AUTOSAR XML (schema 4-2-2)
package /STELLANTIS/EPT/ASWCs
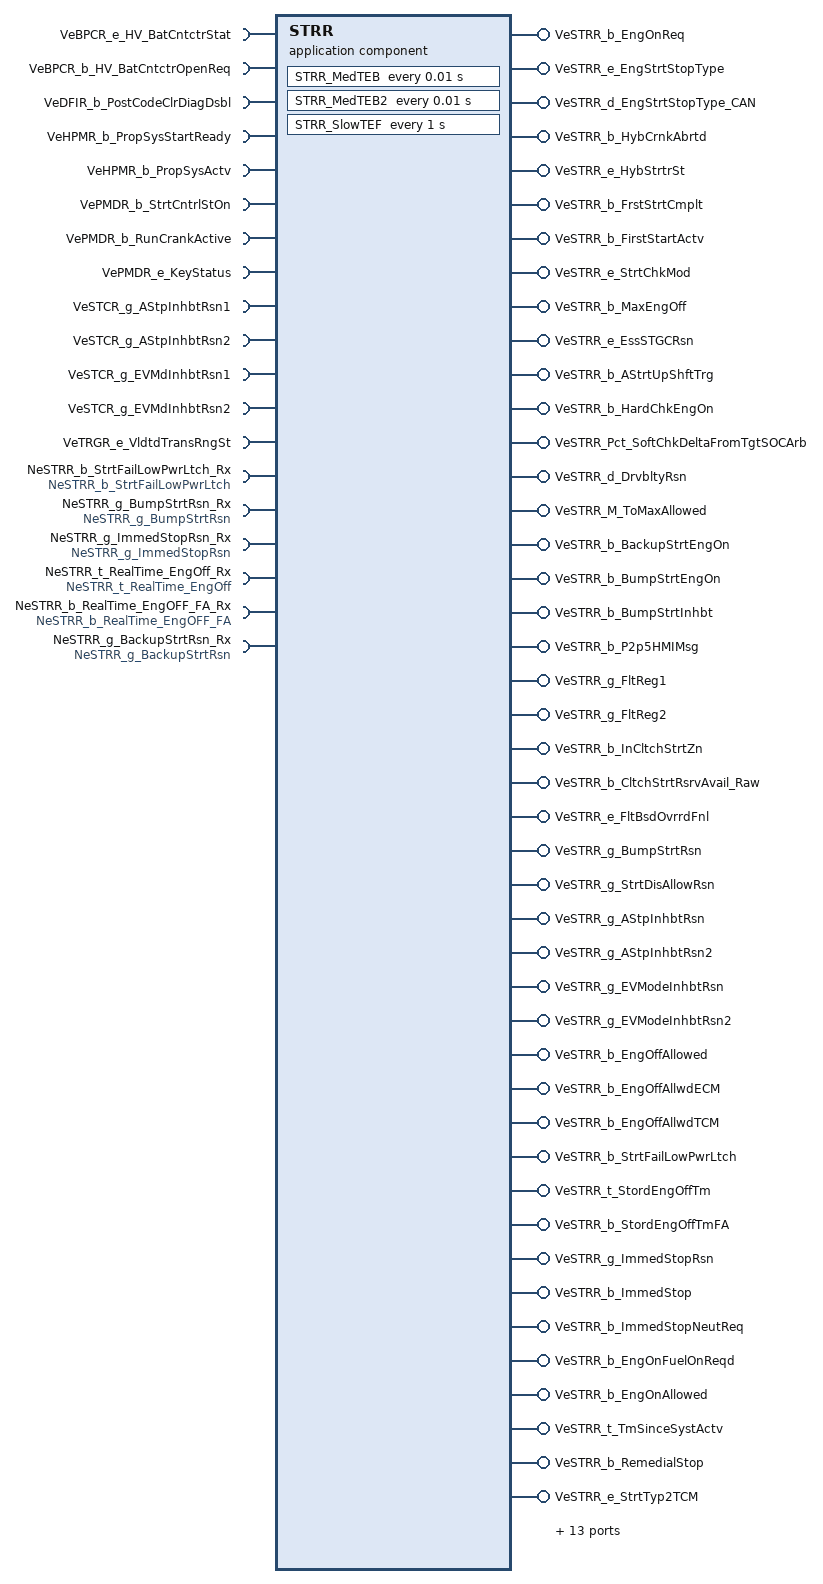
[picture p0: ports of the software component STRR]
  application sw component type STRR
    13 x require port:
      VeBPCR_e_HV_BatCntctrStat: variation-point={short-label=vpVeBPCR_e_HV_BatCntctrStat, sw-syscond=1}, nonqueued-receiver-com-spec{data-element=Value, init-value=CeHVTR_e_Open}, required-interface=VeBPCR_e_HV_BatCntctrStat
      VeBPCR_b_HV_BatCntctrOpenReq: variation-point={short-label=vpVeBPCR_b_HV_BatCntctrOpenReq, sw-syscond=1}, nonqueued-receiver-com-spec{data-element=Value, init-value=0}, required-interface=VeBPCR_b_HV_BatCntctrOpenReq
      VeDFIR_b_PostCodeClrDiagDsbl: variation-point={short-label=vpVeDFIR_b_PostCodeClrDiagDsbl, sw-syscond=1}, nonqueued-receiver-com-spec{data-element=Value, init-value=0}, required-interface=VeDFIR_b_PostCodeClrDiagDsbl
      VeHPMR_b_PropSysStartReady: variation-point={short-label=vpVeHPMR_b_PropSysStartReady, sw-syscond=1}, nonqueued-receiver-com-spec{data-element=Value, init-value=0}, required-interface=VeHPMR_b_PropSysStartReady
      VeHPMR_b_PropSysActv: nonqueued-receiver-com-spec{data-element=Value, init-value=0}, required-interface=VeHPMR_b_PropSysActv
      VePMDR_b_StrtCntrlStOn: nonqueued-receiver-com-spec{data-element=Value, init-value=0}, required-interface=VePMDR_b_StrtCntrlStOn
      VePMDR_b_RunCrankActive: variation-point={short-label=vpVePMDR_b_RunCrankActive, sw-syscond=1}, nonqueued-receiver-com-spec{data-element=Value, init-value=0}, required-interface=VePMDR_b_RunCrankActive
      VePMDR_e_KeyStatus: variation-point={short-label=vpVePMDR_e_KeyStatus, sw-syscond=1}, nonqueued-receiver-com-spec{data-element=Value, init-value=CePMDR_e_KeySt_Off}, required-interface=VePMDR_e_KeyStatus
      VeSTCR_g_AStpInhbtRsn1: nonqueued-receiver-com-spec{data-element=Value, init-value=0}, required-interface=VeSTCR_g_AStpInhbtRsn1
      VeSTCR_g_AStpInhbtRsn2: nonqueued-receiver-com-spec{data-element=Value, init-value=0}, required-interface=VeSTCR_g_AStpInhbtRsn2
      VeSTCR_g_EVMdInhbtRsn1: nonqueued-receiver-com-spec{data-element=Value, init-value=0}, required-interface=VeSTCR_g_EVMdInhbtRsn1
      VeSTCR_g_EVMdInhbtRsn2: nonqueued-receiver-com-spec{data-element=Value, init-value=0}, required-interface=VeSTCR_g_EVMdInhbtRsn2
      VeTRGR_e_VldtdTransRngSt: variation-point={short-label=vpVeTRGR_e_VldtdTransRngSt, sw-syscond=1}, nonqueued-receiver-com-spec{data-element=Value, init-value=CeTRGR_e_NoSelectionAvailable}, required-interface=VeTRGR_e_VldtdTransRngSt
    51 x provide port:
      VeSTRR_b_EngOnReq: nonqueued-sender-com-spec{data-element=Value, init-value=0}, provided-interface=VeSTRR_b_EngOnReq
      VeSTRR_e_EngStrtStopType: nonqueued-sender-com-spec{data-element=Value, init-value=CeSTRR_e_NoAction}, provided-interface=VeSTRR_e_EngStrtStopType
      VeSTRR_d_EngStrtStopType_CAN: nonqueued-sender-com-spec{data-element=Value, init-value=0}, provided-interface=VeSTRR_d_EngStrtStopType_CAN
      VeSTRR_b_HybCrnkAbrtd: nonqueued-sender-com-spec{data-element=Value, init-value=0}, provided-interface=VeSTRR_b_HybCrnkAbrtd
      VeSTRR_e_HybStrtrSt: nonqueued-sender-com-spec{data-element=Value, init-value=CeSTRR_e_KeyOffSt}, provided-interface=VeSTRR_e_HybStrtrSt
      VeSTRR_b_FrstStrtCmplt: nonqueued-sender-com-spec{data-element=Value, init-value=0}, provided-interface=VeSTRR_b_FrstStrtCmplt
      VeSTRR_b_FirstStartActv: nonqueued-sender-com-spec{data-element=Value, init-value=0}, provided-interface=VeSTRR_b_FirstStartActv
      VeSTRR_e_StrtChkMod: nonqueued-sender-com-spec{data-element=Value, init-value=CeSTRR_e_Normal}, provided-interface=VeSTRR_e_StrtChkMod
      VeSTRR_b_MaxEngOff: nonqueued-sender-com-spec{data-element=Value, init-value=0}, provided-interface=VeSTRR_b_MaxEngOff
      VeSTRR_e_EssSTGCRsn: nonqueued-sender-com-spec{data-element=Value, init-value=CeSTRR_e_None}, provided-interface=VeSTRR_e_EssSTGCRsn
      VeSTRR_b_AStrtUpShftTrg: nonqueued-sender-com-spec{data-element=Value, init-value=0}, provided-interface=VeSTRR_b_AStrtUpShftTrg
      VeSTRR_b_HardChkEngOn: nonqueued-sender-com-spec{data-element=Value, init-value=0}, provided-interface=VeSTRR_b_HardChkEngOn
      VeSTRR_Pct_SoftChkDeltaFromTgtSOCArb: nonqueued-sender-com-spec{data-element=Value, init-value=0}, provided-interface=VeSTRR_Pct_SoftChkDeltaFromTgtSOCArb
      VeSTRR_d_DrvbltyRsn: nonqueued-sender-com-spec{data-element=Value, init-value=0}, provided-interface=VeSTRR_d_DrvbltyRsn
      VeSTRR_M_ToMaxAllowed: nonqueued-sender-com-spec{data-element=Value, init-value=0}, provided-interface=VeSTRR_M_ToMaxAllowed
      VeSTRR_b_BackupStrtEngOn: nonqueued-sender-com-spec{data-element=Value, init-value=0}, provided-interface=VeSTRR_b_BackupStrtEngOn
      VeSTRR_b_BumpStrtEngOn: nonqueued-sender-com-spec{data-element=Value, init-value=0}, provided-interface=VeSTRR_b_BumpStrtEngOn
      VeSTRR_b_BumpStrtInhbt: nonqueued-sender-com-spec{data-element=Value, init-value=0}, provided-interface=VeSTRR_b_BumpStrtInhbt
      VeSTRR_b_P2p5HMIMsg: nonqueued-sender-com-spec{data-element=Value, init-value=0}, provided-interface=VeSTRR_b_P2p5HMIMsg
      VeSTRR_g_FltReg1: nonqueued-sender-com-spec{data-element=Value, init-value=0}, provided-interface=VeSTRR_g_FltReg1
      VeSTRR_g_FltReg2: nonqueued-sender-com-spec{data-element=Value, init-value=0}, provided-interface=VeSTRR_g_FltReg2
      VeSTRR_b_InCltchStrtZn: nonqueued-sender-com-spec{data-element=Value, init-value=0}, provided-interface=VeSTRR_b_InCltchStrtZn
      VeSTRR_b_CltchStrtRsrvAvail_Raw: nonqueued-sender-com-spec{data-element=Value, init-value=0}, provided-interface=VeSTRR_b_CltchStrtRsrvAvail_Raw
      VeSTRR_e_FltBsdOvrrdFnl: nonqueued-sender-com-spec{data-element=Value, init-value=CeSTRR_e_NoOvrrd}, provided-interface=VeSTRR_e_FltBsdOvrrdFnl
      VeSTRR_g_BumpStrtRsn: nonqueued-sender-com-spec{data-element=Value, init-value=0}, provided-interface=VeSTRR_g_BumpStrtRsn
      VeSTRR_g_StrtDisAllowRsn: nonqueued-sender-com-spec{data-element=Value, init-value=0}, provided-interface=VeSTRR_g_StrtDisAllowRsn
      VeSTRR_g_AStpInhbtRsn: nonqueued-sender-com-spec{data-element=Value, init-value=0}, provided-interface=VeSTRR_g_AStpInhbtRsn
      VeSTRR_g_AStpInhbtRsn2: nonqueued-sender-com-spec{data-element=Value, init-value=0}, provided-interface=VeSTRR_g_AStpInhbtRsn2
      VeSTRR_g_EVModeInhbtRsn: nonqueued-sender-com-spec{data-element=Value, init-value=0}, provided-interface=VeSTRR_g_EVModeInhbtRsn
      VeSTRR_g_EVModeInhbtRsn2: nonqueued-sender-com-spec{data-element=Value, init-value=0}, provided-interface=VeSTRR_g_EVModeInhbtRsn2
      VeSTRR_b_EngOffAllowed: nonqueued-sender-com-spec{data-element=Value, init-value=0}, provided-interface=VeSTRR_b_EngOffAllowed
      VeSTRR_b_EngOffAllwdECM: nonqueued-sender-com-spec{data-element=Value, init-value=0}, provided-interface=VeSTRR_b_EngOffAllwdECM
      VeSTRR_b_EngOffAllwdTCM: nonqueued-sender-com-spec{data-element=Value, init-value=0}, provided-interface=VeSTRR_b_EngOffAllwdTCM
      VeSTRR_b_StrtFailLowPwrLtch: nonqueued-sender-com-spec{data-element=Value, init-value=0}, provided-interface=VeSTRR_b_StrtFailLowPwrLtch
      VeSTRR_t_StordEngOffTm: nonqueued-sender-com-spec{data-element=Value, init-value=0}, provided-interface=VeSTRR_t_StordEngOffTm
      VeSTRR_b_StordEngOffTmFA: nonqueued-sender-com-spec{data-element=Value, init-value=0}, provided-interface=VeSTRR_b_StordEngOffTmFA
      VeSTRR_g_ImmedStopRsn: nonqueued-sender-com-spec{data-element=Value, init-value=0}, provided-interface=VeSTRR_g_ImmedStopRsn
      VeSTRR_b_ImmedStop: nonqueued-sender-com-spec{data-element=Value, init-value=0}, provided-interface=VeSTRR_b_ImmedStop
      VeSTRR_b_ImmedStopNeutReq: nonqueued-sender-com-spec{data-element=Value, init-value=0}, provided-interface=VeSTRR_b_ImmedStopNeutReq
      VeSTRR_b_EngOnFuelOnReqd: nonqueued-sender-com-spec{data-element=Value, init-value=0}, provided-interface=VeSTRR_b_EngOnFuelOnReqd
      VeSTRR_b_EngOnAllowed: nonqueued-sender-com-spec{data-element=Value, init-value=0}, provided-interface=VeSTRR_b_EngOnAllowed
      VeSTRR_t_TmSinceSystActv: nonqueued-sender-com-spec{data-element=Value, init-value=0}, provided-interface=VeSTRR_t_TmSinceSystActv
      VeSTRR_b_RemedialStop: nonqueued-sender-com-spec{data-element=Value, init-value=0}, provided-interface=VeSTRR_b_RemedialStop
      VeSTRR_e_StrtTyp2TCM: nonqueued-sender-com-spec{data-element=Value, init-value=CeSTRR_e_NoAction}, provided-interface=VeSTRR_e_StrtTyp2TCM
      VeSTRR_b_RemStopESS: nonqueued-sender-com-spec{data-element=Value, init-value=0}, provided-interface=VeSTRR_b_RemStopESS
      VeSTRR_b_FCOnAllwd: nonqueued-sender-com-spec{data-element=Value, init-value=0}, provided-interface=VeSTRR_b_FCOnAllwd
      VeSTRR_b_FCOffAllwd: nonqueued-sender-com-spec{data-element=Value, init-value=0}, provided-interface=VeSTRR_b_FCOffAllwd
      VeSTRR_e_FCStrtrSt: nonqueued-sender-com-spec{data-element=Value, init-value=CeSTRR_e_KeyOffSt}, provided-interface=VeSTRR_e_FCStrtrSt
      VeSTRR_e_FCSysActv: nonqueued-sender-com-spec{data-element=Value, init-value=CeESSR_e_HybEngDisabled}, provided-interface=VeSTRR_e_FCSysActv
      VeSTRR_e_FCMdReq: nonqueued-sender-com-spec{data-element=Value, init-value=CeSTRR_e_NoOvrd}, provided-interface=VeSTRR_e_FCMdReq
      VeSTRR_P_FCPwrReq: nonqueued-sender-com-spec{data-element=Value, init-value=0}, provided-interface=VeSTRR_P_FCPwrReq
    6 x require port:
      NeSTRR_b_StrtFailLowPwrLtch_Rx: nv-require-com-spec{init-value=0, variable=NeSTRR_b_StrtFailLowPwrLtch}, required-interface=NeSTRR_b_StrtFailLowPwrLtch
      NeSTRR_g_BumpStrtRsn_Rx: nv-require-com-spec{init-value=0, variable=NeSTRR_g_BumpStrtRsn}, required-interface=NeSTRR_g_BumpStrtRsn
      NeSTRR_g_ImmedStopRsn_Rx: nv-require-com-spec{init-value=0, variable=NeSTRR_g_ImmedStopRsn}, required-interface=NeSTRR_g_ImmedStopRsn
      NeSTRR_t_RealTime_EngOff_Rx: nv-require-com-spec{init-value=0, variable=NeSTRR_t_RealTime_EngOff}, required-interface=NeSTRR_t_RealTime_EngOff
      NeSTRR_b_RealTime_EngOFF_FA_Rx: nv-require-com-spec{init-value=0, variable=NeSTRR_b_RealTime_EngOFF_FA}, required-interface=NeSTRR_b_RealTime_EngOFF_FA
      NeSTRR_g_BackupStrtRsn_Rx: nv-require-com-spec{init-value=0, variable=NeSTRR_g_BackupStrtRsn}, required-interface=NeSTRR_g_BackupStrtRsn
    6 x provide port:
      NeSTRR_b_StrtFailLowPwrLtch: nv-provide-com-spec{ram-block-init-value=0, variable=NeSTRR_b_StrtFailLowPwrLtch}, provided-interface=NeSTRR_b_StrtFailLowPwrLtch
      NeSTRR_g_BumpStrtRsn: nv-provide-com-spec{ram-block-init-value=0, variable=NeSTRR_g_BumpStrtRsn}, provided-interface=NeSTRR_g_BumpStrtRsn
      NeSTRR_g_ImmedStopRsn: nv-provide-com-spec{ram-block-init-value=0, variable=NeSTRR_g_ImmedStopRsn}, provided-interface=NeSTRR_g_ImmedStopRsn
      NeSTRR_t_RealTime_EngOff: nv-provide-com-spec{ram-block-init-value=0, variable=NeSTRR_t_RealTime_EngOff}, provided-interface=NeSTRR_t_RealTime_EngOff
      NeSTRR_b_RealTime_EngOFF_FA: nv-provide-com-spec{ram-block-init-value=0, variable=NeSTRR_b_RealTime_EngOFF_FA}, provided-interface=NeSTRR_b_RealTime_EngOFF_FA
      NeSTRR_g_BackupStrtRsn: nv-provide-com-spec{ram-block-init-value=0, variable=NeSTRR_g_BackupStrtRsn}, provided-interface=NeSTRR_g_BackupStrtRsn
    behavior IB_STRR: data-type-mapping=msADTtoIDTMapping, handle-termination-and-restart=NO-SUPPORT, included-data-type-set=data-type=TeSTRR_e_STMTrigger
      timing event Event_MedTEB: start-on-event=STRR_MedTEB, period=0.01
      timing event Event_MedTEB2: start-on-event=STRR_MedTEB2, period=0.01
      timing event Event_SlowTEF: start-on-event=STRR_SlowTEF, period=1
      4 x init event:
        Event_STRR_ac_Init: start-on-event=STRR_ac_Init
        Event_PUP: start-on-event=STRR_PUP
        Event_PwrOn: start-on-event=STRR_PwrOn
        Event_PwrOff: start-on-event=STRR_PwrOff
      7 x runnable:
        STRR_ac_Init
          data-send-points:
            9 x access:
              OUT_VeSTRR_e_EngStrtStopType_Value: accessed-variable=VeSTRR_e_EngStrtStopType.Value
              OUT_VeSTRR_e_HybStrtrSt_Value: accessed-variable=VeSTRR_e_HybStrtrSt.Value
              OUT_VeSTRR_e_StrtChkMod_Value: accessed-variable=VeSTRR_e_StrtChkMod.Value
              OUT_VeSTRR_e_EssSTGCRsn_Value: accessed-variable=VeSTRR_e_EssSTGCRsn.Value
              OUT_VeSTRR_e_FltBsdOvrrdFnl_Value: accessed-variable=VeSTRR_e_FltBsdOvrrdFnl.Value
              OUT_VeSTRR_e_StrtTyp2TCM_Value: accessed-variable=VeSTRR_e_StrtTyp2TCM.Value
              OUT_VeSTRR_e_FCStrtrSt_Value: accessed-variable=VeSTRR_e_FCStrtrSt.Value
              OUT_VeSTRR_e_FCSysActv_Value: accessed-variable=VeSTRR_e_FCSysActv.Value
              OUT_VeSTRR_e_FCMdReq_Value: accessed-variable=VeSTRR_e_FCMdReq.Value
        STRR_PUP
        STRR_MedTEB
          data-receive-point-by-arguments:
            13 x access:
              IN_VeBPCR_b_HV_BatCntctrOpenReq_Value: accessed-variable=VeBPCR_b_HV_BatCntctrOpenReq.Value, variation-point={short-label=vpIN_VeBPCR_b_HV_BatCntctrOpenReq_Value, sw-syscond=1}
              IN_VeBPCR_e_HV_BatCntctrStat_Value: accessed-variable=VeBPCR_e_HV_BatCntctrStat.Value, variation-point={short-label=vpIN_VeBPCR_e_HV_BatCntctrStat_Value, sw-syscond=1}
              IN_VeDFIR_b_PostCodeClrDiagDsbl_Value: accessed-variable=VeDFIR_b_PostCodeClrDiagDsbl.Value, variation-point={short-label=vpIN_VeDFIR_b_PostCodeClrDiagDsbl_Value, sw-syscond=1}
              IN_VeHPMR_b_PropSysActv_Value: accessed-variable=VeHPMR_b_PropSysActv.Value
              IN_VeHPMR_b_PropSysStartReady_Value: accessed-variable=VeHPMR_b_PropSysStartReady.Value, variation-point={short-label=vpIN_VeHPMR_b_PropSysStartReady_Value, sw-syscond=1}
              IN_VePMDR_b_RunCrankActive_Value: accessed-variable=VePMDR_b_RunCrankActive.Value, variation-point={short-label=vpIN_VePMDR_b_RunCrankActive_Value, sw-syscond=1}
              IN_VePMDR_b_StrtCntrlStOn_Value: accessed-variable=VePMDR_b_StrtCntrlStOn.Value
              IN_VePMDR_e_KeyStatus_Value: accessed-variable=VePMDR_e_KeyStatus.Value, variation-point={short-label=vpIN_VePMDR_e_KeyStatus_Value, sw-syscond=1}
              IN_VeSTCR_g_AStpInhbtRsn1_Value: accessed-variable=VeSTCR_g_AStpInhbtRsn1.Value
              IN_VeSTCR_g_AStpInhbtRsn2_Value: accessed-variable=VeSTCR_g_AStpInhbtRsn2.Value
              IN_VeSTCR_g_EVMdInhbtRsn1_Value: accessed-variable=VeSTCR_g_EVMdInhbtRsn1.Value
              IN_VeSTCR_g_EVMdInhbtRsn2_Value: accessed-variable=VeSTCR_g_EVMdInhbtRsn2.Value
              IN_VeTRGR_e_VldtdTransRngSt_Value: accessed-variable=VeTRGR_e_VldtdTransRngSt.Value, variation-point={short-label=vpIN_VeTRGR_e_VldtdTransRngSt_Value, sw-syscond=1}
          data-send-points:
            48 x access:
              OUT_VeSTRR_b_ImmedStop_Value: accessed-variable=VeSTRR_b_ImmedStop.Value
              OUT_VeSTRR_b_ImmedStopNeutReq_Value: accessed-variable=VeSTRR_b_ImmedStopNeutReq.Value
              OUT_VeSTRR_b_EngOnFuelOnReqd_Value: accessed-variable=VeSTRR_b_EngOnFuelOnReqd.Value
              OUT_VeSTRR_b_EngOnAllowed_Value: accessed-variable=VeSTRR_b_EngOnAllowed.Value
              OUT_VeSTRR_b_RemedialStop_Value: accessed-variable=VeSTRR_b_RemedialStop.Value
              OUT_VeSTRR_e_StrtTyp2TCM_Value: accessed-variable=VeSTRR_e_StrtTyp2TCM.Value
              OUT_VeSTRR_b_RemStopESS_Value: accessed-variable=VeSTRR_b_RemStopESS.Value
              OUT_VeSTRR_b_EngOnReq_Value: accessed-variable=VeSTRR_b_EngOnReq.Value
              OUT_VeSTRR_e_EngStrtStopType_Value: accessed-variable=VeSTRR_e_EngStrtStopType.Value
              OUT_VeSTRR_d_EngStrtStopType_CAN_Value: accessed-variable=VeSTRR_d_EngStrtStopType_CAN.Value
              OUT_VeSTRR_b_HybCrnkAbrtd_Value: accessed-variable=VeSTRR_b_HybCrnkAbrtd.Value
              OUT_VeSTRR_e_HybStrtrSt_Value: accessed-variable=VeSTRR_e_HybStrtrSt.Value
              OUT_VeSTRR_b_FrstStrtCmplt_Value: accessed-variable=VeSTRR_b_FrstStrtCmplt.Value
              OUT_VeSTRR_b_FirstStartActv_Value: accessed-variable=VeSTRR_b_FirstStartActv.Value
              OUT_VeSTRR_e_StrtChkMod_Value: accessed-variable=VeSTRR_e_StrtChkMod.Value
              OUT_VeSTRR_b_MaxEngOff_Value: accessed-variable=VeSTRR_b_MaxEngOff.Value
              OUT_VeSTRR_e_EssSTGCRsn_Value: accessed-variable=VeSTRR_e_EssSTGCRsn.Value
              OUT_VeSTRR_b_AStrtUpShftTrg_Value: accessed-variable=VeSTRR_b_AStrtUpShftTrg.Value
              OUT_VeSTRR_b_HardChkEngOn_Value: accessed-variable=VeSTRR_b_HardChkEngOn.Value
              OUT_VeSTRR_Pct_SoftChkDeltaFromTgtSOCArb_Value: accessed-variable=VeSTRR_Pct_SoftChkDeltaFromTgtSOCArb.Value
              OUT_VeSTRR_d_DrvbltyRsn_Value: accessed-variable=VeSTRR_d_DrvbltyRsn.Value
              OUT_VeSTRR_M_ToMaxAllowed_Value: accessed-variable=VeSTRR_M_ToMaxAllowed.Value
              OUT_VeSTRR_b_BackupStrtEngOn_Value: accessed-variable=VeSTRR_b_BackupStrtEngOn.Value
              OUT_VeSTRR_b_BumpStrtEngOn_Value: accessed-variable=VeSTRR_b_BumpStrtEngOn.Value
              OUT_VeSTRR_b_BumpStrtInhbt_Value: accessed-variable=VeSTRR_b_BumpStrtInhbt.Value
              OUT_VeSTRR_b_P2p5HMIMsg_Value: accessed-variable=VeSTRR_b_P2p5HMIMsg.Value
              OUT_VeSTRR_b_InCltchStrtZn_Value: accessed-variable=VeSTRR_b_InCltchStrtZn.Value
              OUT_VeSTRR_b_CltchStrtRsrvAvail_Raw_Value: accessed-variable=VeSTRR_b_CltchStrtRsrvAvail_Raw.Value
              OUT_VeSTRR_e_FltBsdOvrrdFnl_Value: accessed-variable=VeSTRR_e_FltBsdOvrrdFnl.Value
              OUT_VeSTRR_g_BumpStrtRsn_Value: accessed-variable=VeSTRR_g_BumpStrtRsn.Value
              OUT_VeSTRR_g_StrtDisAllowRsn_Value: accessed-variable=VeSTRR_g_StrtDisAllowRsn.Value
              OUT_VeSTRR_g_AStpInhbtRsn_Value: accessed-variable=VeSTRR_g_AStpInhbtRsn.Value
              OUT_VeSTRR_g_AStpInhbtRsn2_Value: accessed-variable=VeSTRR_g_AStpInhbtRsn2.Value
              OUT_VeSTRR_g_EVModeInhbtRsn_Value: accessed-variable=VeSTRR_g_EVModeInhbtRsn.Value
              OUT_VeSTRR_g_EVModeInhbtRsn2_Value: accessed-variable=VeSTRR_g_EVModeInhbtRsn2.Value
              OUT_VeSTRR_b_EngOffAllowed_Value: accessed-variable=VeSTRR_b_EngOffAllowed.Value
              OUT_VeSTRR_b_EngOffAllwdECM_Value: accessed-variable=VeSTRR_b_EngOffAllwdECM.Value
              OUT_VeSTRR_b_EngOffAllwdTCM_Value: accessed-variable=VeSTRR_b_EngOffAllwdTCM.Value
              OUT_VeSTRR_b_StrtFailLowPwrLtch_Value: accessed-variable=VeSTRR_b_StrtFailLowPwrLtch.Value
              OUT_VeSTRR_t_StordEngOffTm_Value: accessed-variable=VeSTRR_t_StordEngOffTm.Value
              OUT_VeSTRR_b_StordEngOffTmFA_Value: accessed-variable=VeSTRR_b_StordEngOffTmFA.Value
              OUT_VeSTRR_g_ImmedStopRsn_Value: accessed-variable=VeSTRR_g_ImmedStopRsn.Value
              OUT_VeSTRR_b_FCOnAllwd_Value: accessed-variable=VeSTRR_b_FCOnAllwd.Value
              OUT_VeSTRR_b_FCOffAllwd_Value: accessed-variable=VeSTRR_b_FCOffAllwd.Value
              OUT_VeSTRR_e_FCStrtrSt_Value: accessed-variable=VeSTRR_e_FCStrtrSt.Value
              OUT_VeSTRR_e_FCSysActv_Value: accessed-variable=VeSTRR_e_FCSysActv.Value
              OUT_VeSTRR_e_FCMdReq_Value: accessed-variable=VeSTRR_e_FCMdReq.Value
              OUT_VeSTRR_P_FCPwrReq_Value: accessed-variable=VeSTRR_P_FCPwrReq.Value
        STRR_MedTEB2
          data-send-points:
            access OUT_VeSTRR_g_FltReg1_Value: accessed-variable=VeSTRR_g_FltReg1.Value
            access OUT_VeSTRR_g_FltReg2_Value: accessed-variable=VeSTRR_g_FltReg2.Value
        STRR_SlowTEF
          data-receive-point-by-arguments:
            access IN_VeHPMR_b_PropSysActv_Value: accessed-variable=VeHPMR_b_PropSysActv.Value
          data-send-points:
            access OUT_VeSTRR_t_TmSinceSystActv_Value: accessed-variable=VeSTRR_t_TmSinceSystActv.Value
        STRR_PwrOn
          data-receive-point-by-arguments:
            6 x access:
              IN_NeSTRR_b_RealTime_EngOFF_FA_Rx_NeSTRR_b_RealTime_EngOFF_FA: accessed-variable=NeSTRR_b_RealTime_EngOFF_FA_Rx.NeSTRR_b_RealTime_EngOFF_FA
              IN_NeSTRR_b_StrtFailLowPwrLtch_Rx_NeSTRR_b_StrtFailLowPwrLtch: accessed-variable=NeSTRR_b_StrtFailLowPwrLtch_Rx.NeSTRR_b_StrtFailLowPwrLtch
              IN_NeSTRR_g_BackupStrtRsn_Rx_NeSTRR_g_BackupStrtRsn: accessed-variable=NeSTRR_g_BackupStrtRsn_Rx.NeSTRR_g_BackupStrtRsn
              IN_NeSTRR_g_BumpStrtRsn_Rx_NeSTRR_g_BumpStrtRsn: accessed-variable=NeSTRR_g_BumpStrtRsn_Rx.NeSTRR_g_BumpStrtRsn
              IN_NeSTRR_g_ImmedStopRsn_Rx_NeSTRR_g_ImmedStopRsn: accessed-variable=NeSTRR_g_ImmedStopRsn_Rx.NeSTRR_g_ImmedStopRsn
              IN_NeSTRR_t_RealTime_EngOff_Rx_NeSTRR_t_RealTime_EngOff: accessed-variable=NeSTRR_t_RealTime_EngOff_Rx.NeSTRR_t_RealTime_EngOff
          data-send-points:
            51 x access:
              OUT_VeSTRR_b_EngOnReq_Value: accessed-variable=VeSTRR_b_EngOnReq.Value
              OUT_VeSTRR_e_EngStrtStopType_Value: accessed-variable=VeSTRR_e_EngStrtStopType.Value
              OUT_VeSTRR_d_EngStrtStopType_CAN_Value: accessed-variable=VeSTRR_d_EngStrtStopType_CAN.Value
              OUT_VeSTRR_b_HybCrnkAbrtd_Value: accessed-variable=VeSTRR_b_HybCrnkAbrtd.Value
              OUT_VeSTRR_e_HybStrtrSt_Value: accessed-variable=VeSTRR_e_HybStrtrSt.Value
              OUT_VeSTRR_b_FrstStrtCmplt_Value: accessed-variable=VeSTRR_b_FrstStrtCmplt.Value
              OUT_VeSTRR_b_FirstStartActv_Value: accessed-variable=VeSTRR_b_FirstStartActv.Value
              OUT_VeSTRR_e_StrtChkMod_Value: accessed-variable=VeSTRR_e_StrtChkMod.Value
              OUT_VeSTRR_b_MaxEngOff_Value: accessed-variable=VeSTRR_b_MaxEngOff.Value
              OUT_VeSTRR_e_EssSTGCRsn_Value: accessed-variable=VeSTRR_e_EssSTGCRsn.Value
              OUT_VeSTRR_b_AStrtUpShftTrg_Value: accessed-variable=VeSTRR_b_AStrtUpShftTrg.Value
              OUT_VeSTRR_b_HardChkEngOn_Value: accessed-variable=VeSTRR_b_HardChkEngOn.Value
              OUT_VeSTRR_Pct_SoftChkDeltaFromTgtSOCArb_Value: accessed-variable=VeSTRR_Pct_SoftChkDeltaFromTgtSOCArb.Value
              OUT_VeSTRR_d_DrvbltyRsn_Value: accessed-variable=VeSTRR_d_DrvbltyRsn.Value
              OUT_VeSTRR_M_ToMaxAllowed_Value: accessed-variable=VeSTRR_M_ToMaxAllowed.Value
              OUT_VeSTRR_b_BackupStrtEngOn_Value: accessed-variable=VeSTRR_b_BackupStrtEngOn.Value
              OUT_VeSTRR_b_BumpStrtEngOn_Value: accessed-variable=VeSTRR_b_BumpStrtEngOn.Value
              OUT_VeSTRR_b_BumpStrtInhbt_Value: accessed-variable=VeSTRR_b_BumpStrtInhbt.Value
              OUT_VeSTRR_b_P2p5HMIMsg_Value: accessed-variable=VeSTRR_b_P2p5HMIMsg.Value
              OUT_VeSTRR_g_FltReg1_Value: accessed-variable=VeSTRR_g_FltReg1.Value
              OUT_VeSTRR_g_FltReg2_Value: accessed-variable=VeSTRR_g_FltReg2.Value
              OUT_VeSTRR_b_InCltchStrtZn_Value: accessed-variable=VeSTRR_b_InCltchStrtZn.Value
              OUT_VeSTRR_b_CltchStrtRsrvAvail_Raw_Value: accessed-variable=VeSTRR_b_CltchStrtRsrvAvail_Raw.Value
              OUT_VeSTRR_e_FltBsdOvrrdFnl_Value: accessed-variable=VeSTRR_e_FltBsdOvrrdFnl.Value
              OUT_VeSTRR_g_BumpStrtRsn_Value: accessed-variable=VeSTRR_g_BumpStrtRsn.Value
              OUT_VeSTRR_g_StrtDisAllowRsn_Value: accessed-variable=VeSTRR_g_StrtDisAllowRsn.Value
              OUT_VeSTRR_g_AStpInhbtRsn_Value: accessed-variable=VeSTRR_g_AStpInhbtRsn.Value
              OUT_VeSTRR_g_AStpInhbtRsn2_Value: accessed-variable=VeSTRR_g_AStpInhbtRsn2.Value
              OUT_VeSTRR_g_EVModeInhbtRsn_Value: accessed-variable=VeSTRR_g_EVModeInhbtRsn.Value
              OUT_VeSTRR_g_EVModeInhbtRsn2_Value: accessed-variable=VeSTRR_g_EVModeInhbtRsn2.Value
              OUT_VeSTRR_b_EngOffAllowed_Value: accessed-variable=VeSTRR_b_EngOffAllowed.Value
              OUT_VeSTRR_b_EngOffAllwdECM_Value: accessed-variable=VeSTRR_b_EngOffAllwdECM.Value
              OUT_VeSTRR_b_EngOffAllwdTCM_Value: accessed-variable=VeSTRR_b_EngOffAllwdTCM.Value
              OUT_VeSTRR_b_StrtFailLowPwrLtch_Value: accessed-variable=VeSTRR_b_StrtFailLowPwrLtch.Value
              OUT_VeSTRR_t_StordEngOffTm_Value: accessed-variable=VeSTRR_t_StordEngOffTm.Value
              OUT_VeSTRR_b_StordEngOffTmFA_Value: accessed-variable=VeSTRR_b_StordEngOffTmFA.Value
              OUT_VeSTRR_g_ImmedStopRsn_Value: accessed-variable=VeSTRR_g_ImmedStopRsn.Value
              OUT_VeSTRR_b_ImmedStop_Value: accessed-variable=VeSTRR_b_ImmedStop.Value
              OUT_VeSTRR_b_ImmedStopNeutReq_Value: accessed-variable=VeSTRR_b_ImmedStopNeutReq.Value
              OUT_VeSTRR_b_EngOnFuelOnReqd_Value: accessed-variable=VeSTRR_b_EngOnFuelOnReqd.Value
              OUT_VeSTRR_b_EngOnAllowed_Value: accessed-variable=VeSTRR_b_EngOnAllowed.Value
              OUT_VeSTRR_t_TmSinceSystActv_Value: accessed-variable=VeSTRR_t_TmSinceSystActv.Value
              OUT_VeSTRR_b_RemedialStop_Value: accessed-variable=VeSTRR_b_RemedialStop.Value
              OUT_VeSTRR_e_StrtTyp2TCM_Value: accessed-variable=VeSTRR_e_StrtTyp2TCM.Value
              OUT_VeSTRR_b_RemStopESS_Value: accessed-variable=VeSTRR_b_RemStopESS.Value
              OUT_VeSTRR_b_FCOnAllwd_Value: accessed-variable=VeSTRR_b_FCOnAllwd.Value
              OUT_VeSTRR_b_FCOffAllwd_Value: accessed-variable=VeSTRR_b_FCOffAllwd.Value
              OUT_VeSTRR_e_FCStrtrSt_Value: accessed-variable=VeSTRR_e_FCStrtrSt.Value
              OUT_VeSTRR_e_FCSysActv_Value: accessed-variable=VeSTRR_e_FCSysActv.Value
              OUT_VeSTRR_P_FCPwrReq_Value: accessed-variable=VeSTRR_P_FCPwrReq.Value
              OUT_VeSTRR_e_FCMdReq_Value: accessed-variable=VeSTRR_e_FCMdReq.Value
        STRR_PwrOff
          data-send-points:
            6 x access:
              OUT_NeSTRR_b_StrtFailLowPwrLtch_NeSTRR_b_StrtFailLowPwrLtch: accessed-variable=NeSTRR_b_StrtFailLowPwrLtch.NeSTRR_b_StrtFailLowPwrLtch
              OUT_NeSTRR_g_BumpStrtRsn_NeSTRR_g_BumpStrtRsn: accessed-variable=NeSTRR_g_BumpStrtRsn.NeSTRR_g_BumpStrtRsn
              OUT_NeSTRR_g_ImmedStopRsn_NeSTRR_g_ImmedStopRsn: accessed-variable=NeSTRR_g_ImmedStopRsn.NeSTRR_g_ImmedStopRsn
              OUT_NeSTRR_t_RealTime_EngOff_NeSTRR_t_RealTime_EngOff: accessed-variable=NeSTRR_t_RealTime_EngOff.NeSTRR_t_RealTime_EngOff
              OUT_NeSTRR_b_RealTime_EngOFF_FA_NeSTRR_b_RealTime_EngOFF_FA: accessed-variable=NeSTRR_b_RealTime_EngOFF_FA.NeSTRR_b_RealTime_EngOFF_FA
              OUT_NeSTRR_g_BackupStrtRsn_NeSTRR_g_BackupStrtRsn: accessed-variable=NeSTRR_g_BackupStrtRsn.NeSTRR_g_BackupStrtRsn
      5 x variation point proxy, all with category=CONDITION:
        Variant_STRR_EnblBckUpStrt: condition-access=0
        Variant_STRR_EnblBmpStrt: condition-access=0
        Variant_STRR_UseBEVVar: condition-access=1
        Variant_STRR_UseFCVar: condition-access=0
        Variant_STRR_UseHybVar: condition-access=0
